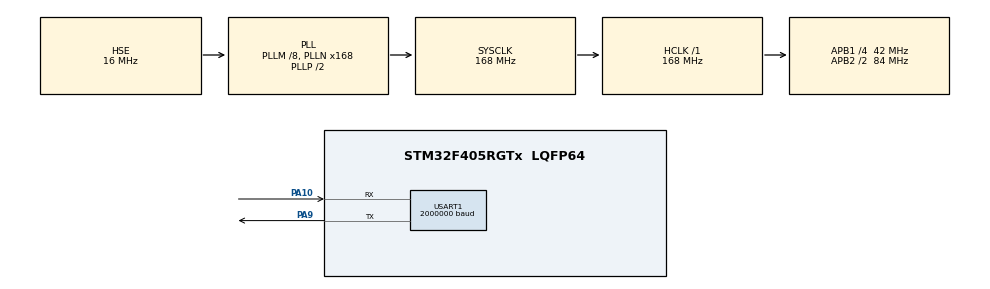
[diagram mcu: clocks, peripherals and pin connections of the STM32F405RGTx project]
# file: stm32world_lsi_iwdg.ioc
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IWDG.Prescaler=IWDG_PRESCALER_16
IWDG.Reload=3000
Mcu.Family=STM32F4
Mcu.Name=STM32F405RGTx
Mcu.Package=LQFP64
NVIC.PriorityGroup=NVIC_PRIORITYGROUP_4
NVIC.TIM5_IRQn=true\:0\:0\:false\:false\:true\:true\:true\:true
NVIC.TIM6_DAC_IRQn=true\:0\:0\:false\:false\:true\:true\:true\:true
PA10.Mode=Asynchronous
PA10.Signal=USART1_RX
PA13.Mode=Trace_Asynchronous_SW
PA13.Signal=SYS_JTMS-SWDIO
PA14.Mode=Trace_Asynchronous_SW
PA14.Signal=SYS_JTCK-SWCLK
PA9.Mode=Asynchronous
PA9.Signal=USART1_TX
PB3.Mode=Trace_Asynchronous_SW
PB3.Signal=SYS_JTDO-SWO
PH0-OSC_IN.Mode=HSE-External-Oscillator
PH0-OSC_IN.Signal=RCC_OSC_IN
PH1-OSC_OUT.Mode=HSE-External-Oscillator
PH1-OSC_OUT.Signal=RCC_OSC_OUT
ProjectManager.HeapSize=0x200
ProjectManager.StackSize=0x400
ProjectManager.TargetToolchain=STM32CubeIDE
RCC.48MHZClocksFreq_Value=84000000
RCC.AHBFreq_Value=168000000
RCC.APB1CLKDivider=RCC_HCLK_DIV4
RCC.APB1Freq_Value=42000000
RCC.APB1TimFreq_Value=84000000
RCC.APB2CLKDivider=RCC_HCLK_DIV2
RCC.APB2Freq_Value=84000000
RCC.APB2TimFreq_Value=168000000
RCC.CortexFreq_Value=168000000
RCC.HCLKFreq_Value=168000000
RCC.HSE_VALUE=16000000
RCC.HSI_VALUE=16000000
RCC.LSE_VALUE=32768
RCC.PLLM=8
RCC.PLLN=168
RCC.PLLSourceVirtual=RCC_PLLSOURCE_HSE
RCC.RCC_MCO1Source=RCC_MCO1SOURCE_HSE
RCC.RCC_RTC_Clock_Source=RCC_RTCCLKSOURCE_LSI
RCC.RCC_RTC_Clock_SourceVirtual=RCC_RTCCLKSOURCE_LSI
RCC.SYSCLKFreq_VALUE=168000000
RCC.SYSCLKSource=RCC_SYSCLKSOURCE_PLLCLK
RCC.VCOOutputFreq_Value=336000000
TIM5.AutoReloadPreload=TIM_AUTORELOAD_PRELOAD_DISABLE
TIM5.Channel-Input_Capture4_from_TI4_Remap=TIM_CHANNEL_4
TIM5.CounterMode=TIM_COUNTERMODE_UP
TIM5.ICFilter_CH4=0
TIM5.ICPolarity_CH4=TIM_INPUTCHANNELPOLARITY_RISING
TIM5.Period=4294967295
TIM5.Prescaler=0
TIM5.TIM_MasterOutputTrigger=TIM_TRGO_RESET
TIM5.TIM_MasterSlaveMode=TIM_MASTERSLAVEMODE_ENABLE
TIM6.Period=10000 - 1
TIM6.Prescaler=8400 - 1
USART1.BaudRate=2000000
USART1.VirtualMode=VM_ASYNC
VP_IWDG_VS_IWDG.Mode=IWDG_Activate
VP_RTC_VS_RTC_Activate.Mode=RTC_Enabled
VP_TIM5_VS_ClockSourceINT.Mode=Internal
VP_TIM5_VS_NoInput4.Mode=Input_Capture4_from_TI4_Remap
VP_TIM6_VS_ClockSourceINT.Mode=Enable_Timer
board=custom

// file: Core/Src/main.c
/* USER CODE BEGIN Header */
/**
 ******************************************************************************
 * @file           : main.c
 * @brief          : Main program body
 ******************************************************************************
 * @attention
 *
 * Copyright (c) 2024 Lars Boegild Thomsen <lbthomsen@gmail.com>
 * All rights reserved.
 *
 * This software is licensed under terms that can be found in the LICENSE file
 * in the root directory of this software component.
 * If no LICENSE file comes with this software, it is provided AS-IS.
 *
 ******************************************************************************
 */
/* USER CODE END Header */
#include "main.h"

/* USER CODE BEGIN Includes */
#include <stdio.h>
/* USER CODE END Includes */

/* USER CODE BEGIN PD */

#define IWDG_REFRESH_INTERVAL 1000 // A case of works for me - but might not work for you

/* USER CODE END PD */

IWDG_HandleTypeDef hiwdg;

RTC_HandleTypeDef hrtc;

TIM_HandleTypeDef htim5;
TIM_HandleTypeDef htim6;

UART_HandleTypeDef huart1;

/* USER CODE BEGIN PV */
uint32_t tim_cnt, last_tim_cnt;
/* USER CODE END PV */

void SystemClock_Config(void);
static void MX_GPIO_Init(void);
static void MX_RTC_Init(void);
static void MX_USART1_UART_Init(void);
static void MX_IWDG_Init(void);
static void MX_TIM5_Init(void);
static void MX_TIM6_Init(void);

/* USER CODE BEGIN 0 */

// Send printf to uart1
int _write(int fd, char *ptr, int len) {
    HAL_StatusTypeDef hstatus;

    if (fd == 1 || fd == 2) {
        hstatus = HAL_UART_Transmit(&huart1, (uint8_t*) ptr, len, HAL_MAX_DELAY);
        if (hstatus == HAL_OK)
            return len;
        else
            return -1;
    }
    return -1;
}

void HAL_TIM_IC_CaptureCallback(TIM_HandleTypeDef *htim) {

    if (htim->Instance == TIM5) {
        ++tim_cnt;
    }

}

void HAL_TIM_PeriodElapsedCallback(TIM_HandleTypeDef *htim) {

    if (htim->Instance == TIM6) {
        last_tim_cnt = tim_cnt;
        tim_cnt = 0;
    }

}

/// @brief  Possible STM32 system reset causes
typedef enum reset_cause_e
{
    RESET_CAUSE_UNKNOWN = 0,
    RESET_CAUSE_LOW_POWER_RESET,
    RESET_CAUSE_WINDOW_WATCHDOG_RESET,
    RESET_CAUSE_INDEPENDENT_WATCHDOG_RESET,
    RESET_CAUSE_SOFTWARE_RESET,
    RESET_CAUSE_POWER_ON_POWER_DOWN_RESET,
    RESET_CAUSE_EXTERNAL_RESET_PIN_RESET,
    RESET_CAUSE_BROWNOUT_RESET,
} reset_cause_t;

/// @brief      Obtain the STM32 system reset cause
/// @param      None
/// @return     The system reset cause
reset_cause_t reset_cause_get(void)
{
    reset_cause_t reset_cause;

    if (__HAL_RCC_GET_FLAG(RCC_FLAG_LPWRRST))
            {
        reset_cause = RESET_CAUSE_LOW_POWER_RESET;
    }
    else if (__HAL_RCC_GET_FLAG(RCC_FLAG_WWDGRST))
            {
        reset_cause = RESET_CAUSE_WINDOW_WATCHDOG_RESET;
    }
    else if (__HAL_RCC_GET_FLAG(RCC_FLAG_IWDGRST))
            {
        reset_cause = RESET_CAUSE_INDEPENDENT_WATCHDOG_RESET;
    }
    else if (__HAL_RCC_GET_FLAG(RCC_FLAG_SFTRST))
            {
        // This reset is induced by calling the ARM CMSIS
        // `NVIC_SystemReset()` function!
        reset_cause = RESET_CAUSE_SOFTWARE_RESET;
    }
    else if (__HAL_RCC_GET_FLAG(RCC_FLAG_PORRST))
            {
        reset_cause = RESET_CAUSE_POWER_ON_POWER_DOWN_RESET;
    }
    else if (__HAL_RCC_GET_FLAG(RCC_FLAG_PINRST))
            {
        reset_cause = RESET_CAUSE_EXTERNAL_RESET_PIN_RESET;
    }
    // Needs to come *after* checking the `RCC_FLAG_PORRST` flag in order to
    // ensure first that the reset cause is NOT a POR/PDR reset. See note
    // below.
    else if (__HAL_RCC_GET_FLAG(RCC_FLAG_BORRST))
            {
        reset_cause = RESET_CAUSE_BROWNOUT_RESET;
    }
    else
    {
        reset_cause = RESET_CAUSE_UNKNOWN;
    }

    // Clear all the reset flags or else they will remain set during future
    // resets until system power is fully removed.
    __HAL_RCC_CLEAR_RESET_FLAGS();

    return reset_cause;
}

// Note: any of the STM32 Hardware Abstraction Layer (HAL) Reset and Clock
// Controller (RCC) header files, such as
// "STM32Cube_FW_F7_V1.12.0/Drivers/STM32F7xx_HAL_Driver/Inc/stm32f7xx_hal_rcc.h",
// "STM32Cube_FW_F2_V1.7.0/Drivers/STM32F2xx_HAL_Driver/Inc/stm32f2xx_hal_rcc.h",
// etc., indicate that the brownout flag, `RCC_FLAG_BORRST`, will be set in
// the event of a "POR/PDR or BOR reset". This means that a Power-On Reset
// (POR), Power-Down Reset (PDR), OR Brownout Reset (BOR) will trip this flag.
// See the doxygen just above their definition for the
// `__HAL_RCC_GET_FLAG()` macro to see this:
//      "@arg RCC_FLAG_BORRST: POR/PDR or BOR reset." <== indicates the Brownout
//      Reset flag will *also* be set in the event of a POR/PDR.
// Therefore, you must check the Brownout Reset flag, `RCC_FLAG_BORRST`, *after*
// first checking the `RCC_FLAG_PORRST` flag in order to ensure first that the
// reset cause is NOT a POR/PDR reset.

/// @brief      Obtain the system reset cause as an ASCII-printable name string
///             from a reset cause type
/// @param[in]  reset_cause     The previously-obtained system reset cause
/// @return     A null-terminated ASCII name string describing the system
///             reset cause
const char* reset_cause_get_name(reset_cause_t reset_cause)
{
    const char *reset_cause_name = "TBD";

    switch (reset_cause)
    {
    case RESET_CAUSE_UNKNOWN:
        reset_cause_name = "UNKNOWN";
        break;
    case RESET_CAUSE_LOW_POWER_RESET:
        reset_cause_name = "LOW_POWER_RESET";
        break;
    case RESET_CAUSE_WINDOW_WATCHDOG_RESET:
        reset_cause_name = "WINDOW_WATCHDOG_RESET";
        break;
    case RESET_CAUSE_INDEPENDENT_WATCHDOG_RESET:
        reset_cause_name = "INDEPENDENT_WATCHDOG_RESET";
        break;
    case RESET_CAUSE_SOFTWARE_RESET:
        reset_cause_name = "SOFTWARE_RESET";
        break;
    case RESET_CAUSE_POWER_ON_POWER_DOWN_RESET:
        reset_cause_name = "POWER-ON_RESET (POR) / POWER-DOWN_RESET (PDR)";
        break;
    case RESET_CAUSE_EXTERNAL_RESET_PIN_RESET:
        reset_cause_name = "EXTERNAL_RESET_PIN_RESET";
        break;
    case RESET_CAUSE_BROWNOUT_RESET:
        reset_cause_name = "BROWNOUT_RESET (BOR)";
        break;
    }

    return reset_cause_name;
}

/* USER CODE END 0 */

int main(void)
{

    /* MCU Configuration--------------------------------------------------------*/

    /* Reset of all peripherals, Initializes the Flash interface and the Systick. */
    HAL_Init();

    /* Configure the system clock */
    SystemClock_Config();

    /* Initialize all configured peripherals */
    MX_GPIO_Init();
    MX_RTC_Init();
    MX_USART1_UART_Init();
    MX_IWDG_Init();
    MX_TIM5_Init();
    MX_TIM6_Init();
    /* USER CODE BEGIN 2 */

    //MX_IWDG_Init();
    printf("\n\n\n--------\nStarting\n");

    reset_cause_t reset_cause = reset_cause_get();
    printf("The system reset cause is \"%s\"\n", reset_cause_get_name(reset_cause));

    HAL_TIM_IC_Start_IT(&htim5, TIM_CHANNEL_4);
    HAL_TIM_Base_Start_IT(&htim6);

    /* USER CODE END 2 */

    /* Infinite loop */
    /* USER CODE BEGIN WHILE */

    uint32_t loop_cnt = 0, now = 0, next_tick = 1000, next_iwdg = 0;

    while (1) {

        now = uwTick;

        if (now >= next_iwdg) {

            HAL_IWDG_Refresh(&hiwdg); // Kick the dog!

            next_iwdg = now + IWDG_REFRESH_INTERVAL;
        }

        if (now >= next_tick) {

            printf("Tick %lu (loop = %lu tim = %lu)\n", now / 1000, loop_cnt, last_tim_cnt);

            // Uncomment to crash app after 10 loops
            //if (now / 1000 >= 10) Error_Handler();

            loop_cnt = 0;
            next_tick = now + 1000;
        }

        ++loop_cnt;
        /* USER CODE END WHILE */

    }
}

void SystemClock_Config(void)
{
    RCC_OscInitTypeDef RCC_OscInitStruct = { 0 };
    RCC_ClkInitTypeDef RCC_ClkInitStruct = { 0 };

    /** Configure the main internal regulator output voltage
     */
    __HAL_RCC_PWR_CLK_ENABLE();
    __HAL_PWR_VOLTAGESCALING_CONFIG(PWR_REGULATOR_VOLTAGE_SCALE1);

    /** Initializes the RCC Oscillators according to the specified parameters
     * in the RCC_OscInitTypeDef structure.
     */
    RCC_OscInitStruct.OscillatorType = RCC_OSCILLATORTYPE_LSI | RCC_OSCILLATORTYPE_HSE;
    RCC_OscInitStruct.HSEState = RCC_HSE_ON;
    RCC_OscInitStruct.LSIState = RCC_LSI_ON;
    RCC_OscInitStruct.PLL.PLLState = RCC_PLL_ON;
    RCC_OscInitStruct.PLL.PLLSource = RCC_PLLSOURCE_HSE;
    RCC_OscInitStruct.PLL.PLLM = 8;
    RCC_OscInitStruct.PLL.PLLN = 168;
    RCC_OscInitStruct.PLL.PLLP = RCC_PLLP_DIV2;
    RCC_OscInitStruct.PLL.PLLQ = 4;
    if (HAL_RCC_OscConfig(&RCC_OscInitStruct) != HAL_OK)
            {
        Error_Handler();
    }

    /** Initializes the CPU, AHB and APB buses clocks
     */
    RCC_ClkInitStruct.ClockType = RCC_CLOCKTYPE_HCLK | RCC_CLOCKTYPE_SYSCLK
            | RCC_CLOCKTYPE_PCLK1 | RCC_CLOCKTYPE_PCLK2;
    RCC_ClkInitStruct.SYSCLKSource = RCC_SYSCLKSOURCE_PLLCLK;
    RCC_ClkInitStruct.AHBCLKDivider = RCC_SYSCLK_DIV1;
    RCC_ClkInitStruct.APB1CLKDivider = RCC_HCLK_DIV4;
    RCC_ClkInitStruct.APB2CLKDivider = RCC_HCLK_DIV2;

    if (HAL_RCC_ClockConfig(&RCC_ClkInitStruct, FLASH_LATENCY_5) != HAL_OK)
            {
        Error_Handler();
    }
}

static void MX_IWDG_Init(void)
{

    hiwdg.Instance = IWDG;
    hiwdg.Init.Prescaler = IWDG_PRESCALER_16;
    hiwdg.Init.Reload = 3000;
    if (HAL_IWDG_Init(&hiwdg) != HAL_OK)
            {
        Error_Handler();
    }

}

static void MX_RTC_Init(void)
{

    /** Initialize RTC Only
     */
    hrtc.Instance = RTC;
    hrtc.Init.HourFormat = RTC_HOURFORMAT_24;
    hrtc.Init.AsynchPrediv = 127;
    hrtc.Init.SynchPrediv = 255;
    hrtc.Init.OutPut = RTC_OUTPUT_DISABLE;
    hrtc.Init.OutPutPolarity = RTC_OUTPUT_POLARITY_HIGH;
    hrtc.Init.OutPutType = RTC_OUTPUT_TYPE_OPENDRAIN;
    if (HAL_RTC_Init(&hrtc) != HAL_OK)
            {
        Error_Handler();
    }

}

static void MX_TIM5_Init(void)
{

    TIM_ClockConfigTypeDef sClockSourceConfig = { 0 };
    TIM_MasterConfigTypeDef sMasterConfig = { 0 };
    TIM_IC_InitTypeDef sConfigIC = { 0 };

    htim5.Instance = TIM5;
    htim5.Init.Prescaler = 0;
    htim5.Init.CounterMode = TIM_COUNTERMODE_UP;
    htim5.Init.Period = 4294967295;
    htim5.Init.ClockDivision = TIM_CLOCKDIVISION_DIV1;
    htim5.Init.AutoReloadPreload = TIM_AUTORELOAD_PRELOAD_DISABLE;
    if (HAL_TIM_Base_Init(&htim5) != HAL_OK)
            {
        Error_Handler();
    }
    sClockSourceConfig.ClockSource = TIM_CLOCKSOURCE_INTERNAL;
    if (HAL_TIM_ConfigClockSource(&htim5, &sClockSourceConfig) != HAL_OK)
            {
        Error_Handler();
    }
    if (HAL_TIM_IC_Init(&htim5) != HAL_OK)
            {
        Error_Handler();
    }
    sMasterConfig.MasterOutputTrigger = TIM_TRGO_RESET;
    sMasterConfig.MasterSlaveMode = TIM_MASTERSLAVEMODE_ENABLE;
    if (HAL_TIMEx_MasterConfigSynchronization(&htim5, &sMasterConfig) != HAL_OK)
            {
        Error_Handler();
    }
    sConfigIC.ICPolarity = TIM_INPUTCHANNELPOLARITY_RISING;
    sConfigIC.ICSelection = TIM_ICSELECTION_DIRECTTI;
    sConfigIC.ICPrescaler = TIM_ICPSC_DIV1;
    sConfigIC.ICFilter = 0;
    if (HAL_TIM_IC_ConfigChannel(&htim5, &sConfigIC, TIM_CHANNEL_4) != HAL_OK)
            {
        Error_Handler();
    }
    if (HAL_TIMEx_RemapConfig(&htim5, TIM_TIM5_LSI) != HAL_OK)
            {
        Error_Handler();
    }

}

static void MX_TIM6_Init(void)
{

    TIM_MasterConfigTypeDef sMasterConfig = { 0 };

    htim6.Instance = TIM6;
    htim6.Init.Prescaler = 8400 - 1;
    htim6.Init.CounterMode = TIM_COUNTERMODE_UP;
    htim6.Init.Period = 10000 - 1;
    htim6.Init.AutoReloadPreload = TIM_AUTORELOAD_PRELOAD_DISABLE;
    if (HAL_TIM_Base_Init(&htim6) != HAL_OK)
            {
        Error_Handler();
    }
    sMasterConfig.MasterOutputTrigger = TIM_TRGO_RESET;
    sMasterConfig.MasterSlaveMode = TIM_MASTERSLAVEMODE_DISABLE;
    if (HAL_TIMEx_MasterConfigSynchronization(&htim6, &sMasterConfig) != HAL_OK)
            {
        Error_Handler();
    }

}

static void MX_USART1_UART_Init(void)
{

    huart1.Instance = USART1;
    huart1.Init.BaudRate = 2000000;
    huart1.Init.WordLength = UART_WORDLENGTH_8B;
    huart1.Init.StopBits = UART_STOPBITS_1;
    huart1.Init.Parity = UART_PARITY_NONE;
    huart1.Init.Mode = UART_MODE_TX_RX;
    huart1.Init.HwFlowCtl = UART_HWCONTROL_NONE;
    huart1.Init.OverSampling = UART_OVERSAMPLING_16;
    if (HAL_UART_Init(&huart1) != HAL_OK)
            {
        Error_Handler();
    }

}

static void MX_GPIO_Init(void)
{

    /* GPIO Ports Clock Enable */
    __HAL_RCC_GPIOH_CLK_ENABLE();
    __HAL_RCC_GPIOA_CLK_ENABLE();
    __HAL_RCC_GPIOB_CLK_ENABLE();

}

void Error_Handler(void)
{
    __disable_irq();
    while (1)
    {
    }
}
